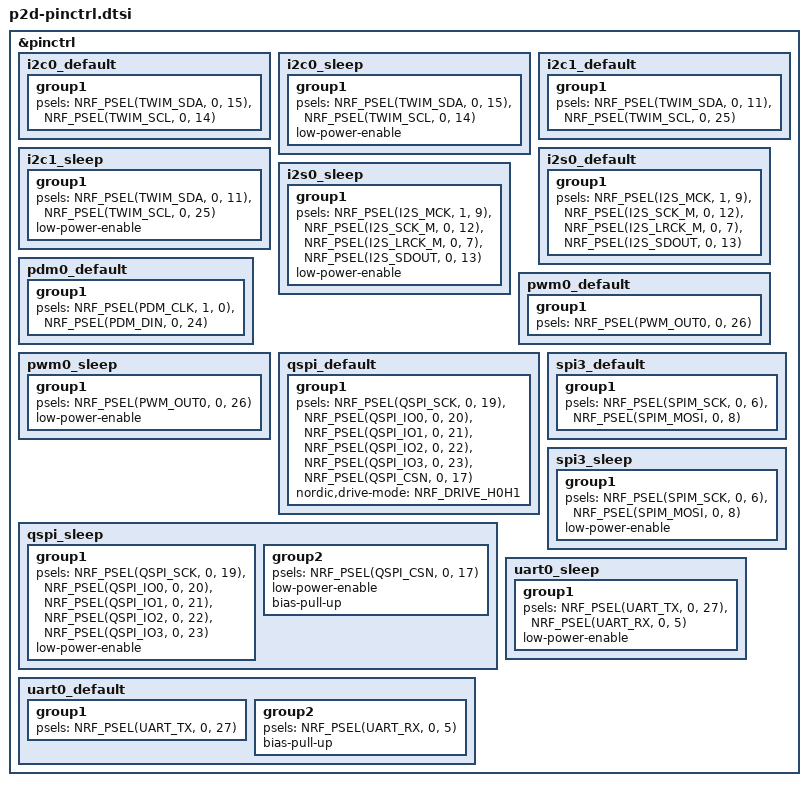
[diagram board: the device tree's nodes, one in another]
/*
 * Copyright (c) 2025 Core Devices LLC
 * SPDX-License-Identifier: Apache-2.0
 */

&pinctrl {
	i2c0_default: i2c0_default {
		group1 {
			psels = <NRF_PSEL(TWIM_SDA, 0, 15)>,
				<NRF_PSEL(TWIM_SCL, 0, 14)>;
		};
	};

	i2c0_sleep: i2c0_sleep {
		group1 {
			psels = <NRF_PSEL(TWIM_SDA, 0, 15)>,
				<NRF_PSEL(TWIM_SCL, 0, 14)>;
			low-power-enable;
		};
	};

	i2c1_default: i2c1_default {
		group1 {
			psels = <NRF_PSEL(TWIM_SDA, 0, 11)>,
				<NRF_PSEL(TWIM_SCL, 0, 25)>;
		};
	};

	i2c1_sleep: i2c1_sleep {
		group1 {
			psels = <NRF_PSEL(TWIM_SDA, 0, 11)>,
				<NRF_PSEL(TWIM_SCL, 0, 25)>;
			low-power-enable;
		};
	};

	i2s0_default: i2s0_default {
		group1 {
			psels = <NRF_PSEL(I2S_MCK, 1, 9)>,
				<NRF_PSEL(I2S_SCK_M, 0, 12)>,
				<NRF_PSEL(I2S_LRCK_M, 0, 7)>,
				<NRF_PSEL(I2S_SDOUT, 0, 13)>;
		};
	};

	i2s0_sleep: i2s0_sleep {
		group1 {
			psels = <NRF_PSEL(I2S_MCK, 1, 9)>,
				<NRF_PSEL(I2S_SCK_M, 0, 12)>,
				<NRF_PSEL(I2S_LRCK_M, 0, 7)>,
				<NRF_PSEL(I2S_SDOUT, 0, 13)>;
			low-power-enable;
		};
	};

	pdm0_default: pdm0_default {
		group1 {
			psels = <NRF_PSEL(PDM_CLK, 1, 0)>,
				<NRF_PSEL(PDM_DIN, 0, 24)>;
		};
	};

	pwm0_default: pwm0_default {
		group1 {
			psels = <NRF_PSEL(PWM_OUT0, 0, 26)>;
		};
	};

	pwm0_sleep: pwm0_sleep {
		group1 {
			psels = <NRF_PSEL(PWM_OUT0, 0, 26)>;
			low-power-enable;
		};
	};

	qspi_default: qspi_default {
		group1 {
			psels = <NRF_PSEL(QSPI_SCK, 0, 19)>,
				<NRF_PSEL(QSPI_IO0, 0, 20)>,
				<NRF_PSEL(QSPI_IO1, 0, 21)>,
				<NRF_PSEL(QSPI_IO2, 0, 22)>,
				<NRF_PSEL(QSPI_IO3, 0, 23)>,
				<NRF_PSEL(QSPI_CSN, 0, 17)>;
			nordic,drive-mode = <NRF_DRIVE_H0H1>;
		};
	};

	qspi_sleep: qspi_sleep {
		group1 {
			psels = <NRF_PSEL(QSPI_SCK, 0, 19)>,
				<NRF_PSEL(QSPI_IO0, 0, 20)>,
				<NRF_PSEL(QSPI_IO1, 0, 21)>,
				<NRF_PSEL(QSPI_IO2, 0, 22)>,
				<NRF_PSEL(QSPI_IO3, 0, 23)>;
			low-power-enable;
		};

		group2 {
			psels = <NRF_PSEL(QSPI_CSN, 0, 17)>;
			low-power-enable;
			bias-pull-up;
		};
	};

	spi3_default: spi3_default {
		group1 {
			psels = <NRF_PSEL(SPIM_SCK, 0, 6)>,
				<NRF_PSEL(SPIM_MOSI, 0, 8)>;
		};
	};

	spi3_sleep: spi3_sleep {
		group1 {
			psels = <NRF_PSEL(SPIM_SCK, 0, 6)>,
				<NRF_PSEL(SPIM_MOSI, 0, 8)>;
			low-power-enable;
		};
	};

	uart0_default: uart0_default {
		group1 {
			psels = <NRF_PSEL(UART_TX, 0, 27)>;
		};

		group2 {
			psels = <NRF_PSEL(UART_RX, 0, 5)>;
			bias-pull-up;
		};
	};

	uart0_sleep: uart0_sleep {
		group1 {
			psels = <NRF_PSEL(UART_TX, 0, 27)>,
				<NRF_PSEL(UART_RX, 0, 5)>;
			low-power-enable;
		};
	};
};
